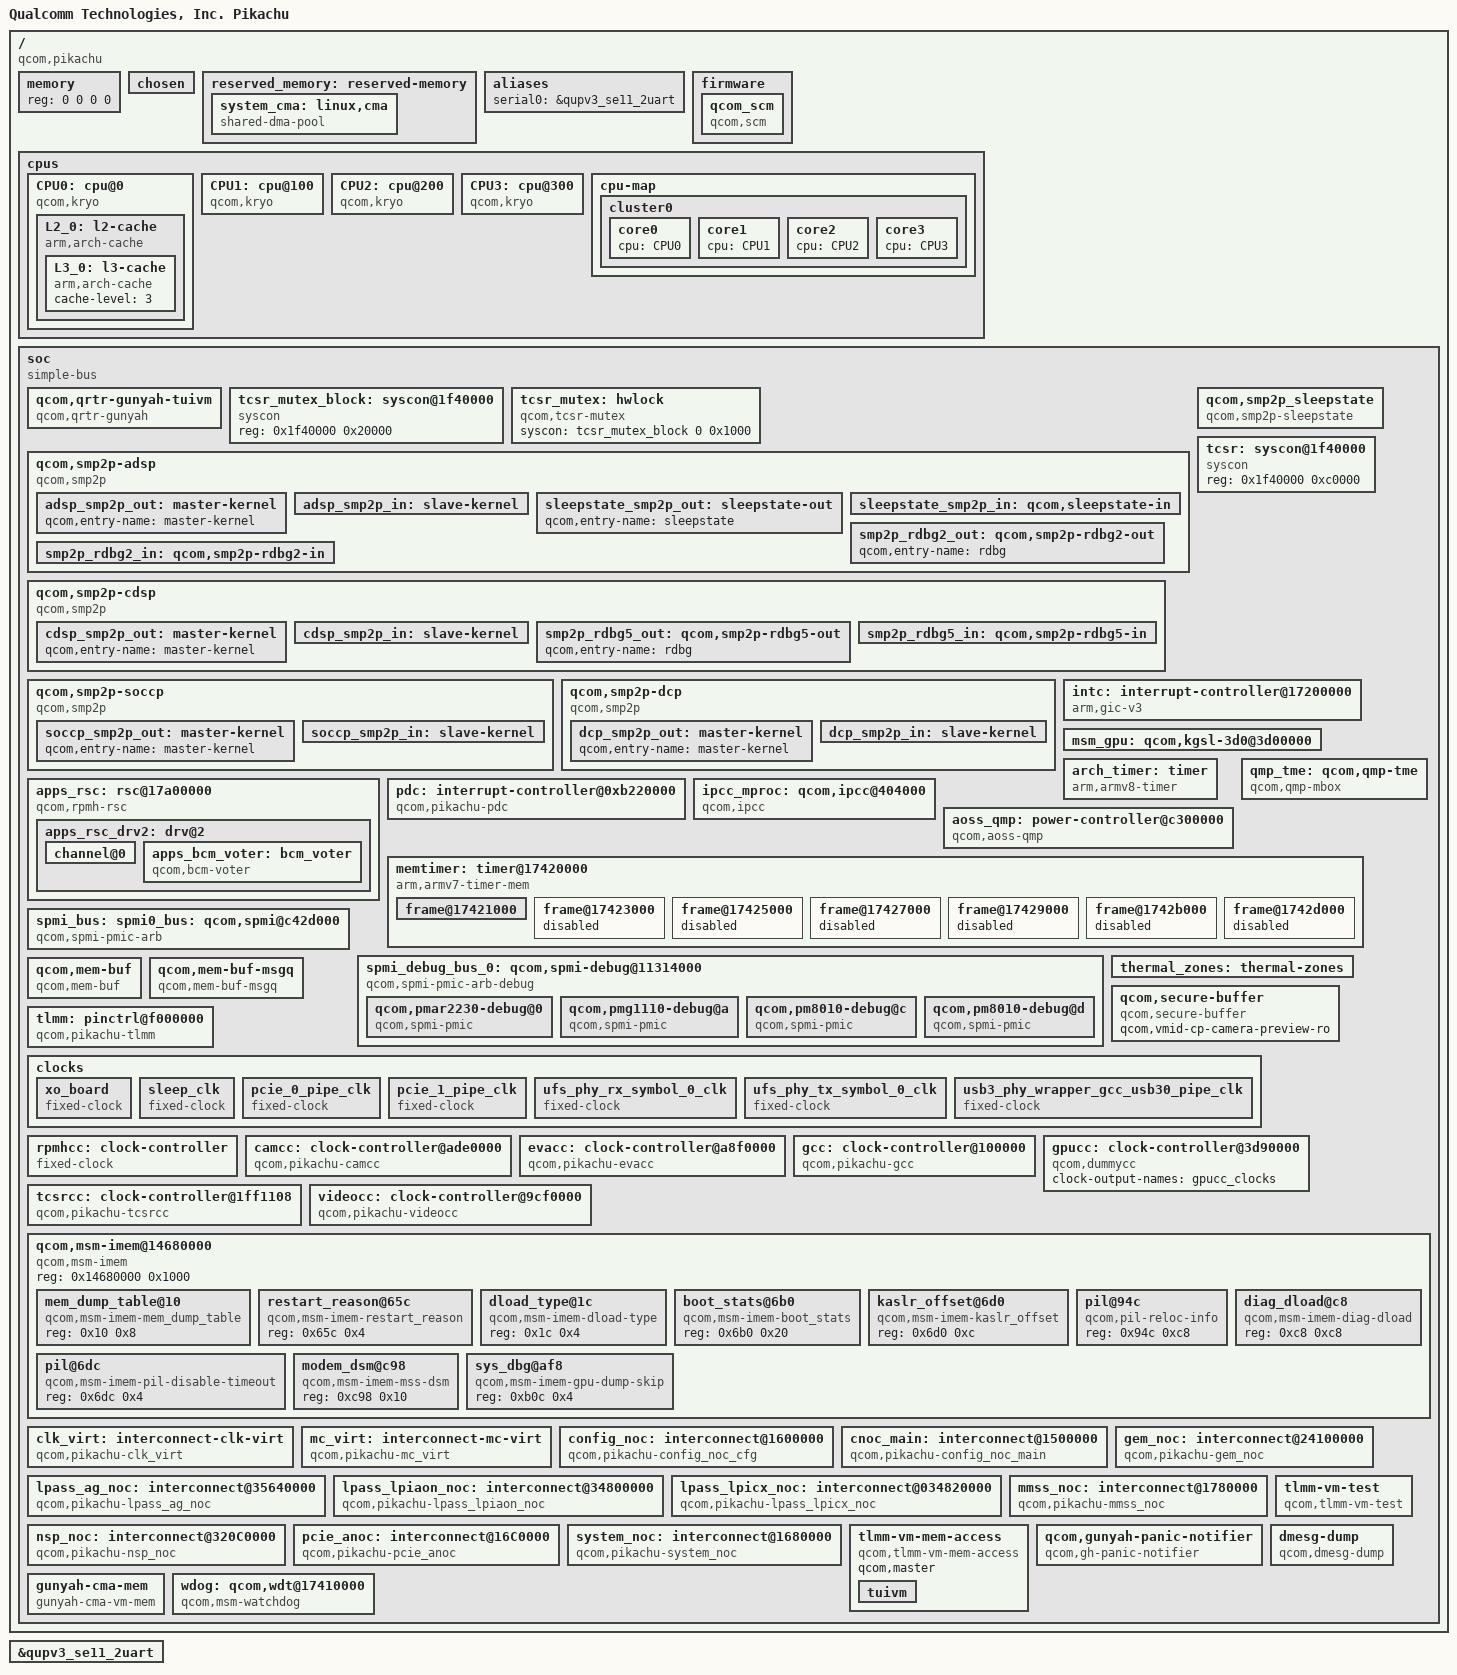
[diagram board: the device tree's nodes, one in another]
// SPDX-License-Identifier: BSD-3-Clause
/*
 * Copyright (c) Qualcomm Technologies, Inc. and/or its subsidiaries.
 */

#include <dt-bindings/interrupt-controller/arm-gic.h>
#include <dt-bindings/clock/qcom,rpmh.h>
#include <dt-bindings/clock/qcom,pikachu-camcc.h>
#include <dt-bindings/clock/qcom,pikachu-evacc.h>
#include <dt-bindings/clock/qcom,pikachu-gcc.h>
#include <dt-bindings/clock/qcom,pikachu-gpucc.h>
#include <dt-bindings/clock/qcom,pikachu-tcsrcc.h>
#include <dt-bindings/clock/qcom,pikachu-videocc.h>
#include <dt-bindings/interconnect/qcom,icc.h>
#include <dt-bindings/interconnect/qcom,pikachu.h>
#include <dt-bindings/regulator/qcom,rpmh-regulator-levels.h>
#include <dt-bindings/soc/qcom,rpmh-rsc.h>
#include <dt-bindings/soc/qcom,ipcc.h>
#include <dt-bindings/spmi/spmi.h>
#include <dt-bindings/mailbox/qcom-ipcc.h>
#include <dt-bindings/interrupt-controller/irq.h>

/ {
	model = "Qualcomm Technologies, Inc. Pikachu";
	compatible = "qcom,pikachu";
	qcom,msm-id = <736 0x10000>;
	interrupt-parent = <&intc>;

	#address-cells = <2>;
	#size-cells = <2>;
	memory { device_type = "memory"; reg = <0 0 0 0>; };

	chosen: chosen {
		bootargs = "kpti=0 log_buf_len=256K swiotlb=0 loop.max_part=7 loglevel=8 swiotlb=0 kasan=off cgroup_disable=pressure cgroup.memory=nokmem,nosocket disable_dma32=on restrict_cma_redirect=false";
	};

	reserved_memory: reserved-memory {};

	aliases {
		serial0 = &qupv3_se11_2uart;
	 };

	firmware: firmware {
		qcom_scm: qcom_scm { };
	};

	cpus {
		#address-cells = <2>;
		#size-cells = <0>;

		CPU0: cpu@0 {
			device_type = "cpu";
			compatible = "qcom,kryo";
			reg = <0x0 0x0>;
			enable-method = "spin-table";
			cpu-release-addr = <0x0 0x90000000>;
			next-level-cache = <&L2_0>;
			capacity-dmips-mhz = <1024>;
			dynamic-power-coefficient = <100>;
			#cooling-cells = <2>;
			L2_0: l2-cache {
				compatible = "arm,arch-cache";
				cache-level = <2>;
				next-level-cache = <&L3_0>;

				L3_0: l3-cache {
					compatible = "arm,arch-cache";
					cache-level = <3>;
				};
			};
		};

		CPU1: cpu@100 {
			device_type = "cpu";
			compatible = "qcom,kryo";
			reg = <0x0 0x100>;
			enable-method = "spin-table";
			cpu-release-addr = <0x0 0x90000000>;
			next-level-cache = <&L2_0>;
			capacity-dmips-mhz = <1024>;
			dynamic-power-coefficient = <100>;
			#cooling-cells = <2>;
		};

		CPU2: cpu@200 {
			device_type = "cpu";
			compatible = "qcom,kryo";
			reg = <0x0 0x200>;
			enable-method = "spin-table";
			cpu-release-addr = <0x0 0x90000000>;
			next-level-cache = <&L2_0>;
			capacity-dmips-mhz = <1024>;
			dynamic-power-coefficient = <100>;
			#cooling-cells = <2>;
		};

		CPU3: cpu@300 {
			device_type = "cpu";
			compatible = "qcom,kryo";
			reg = <0x0 0x300>;
			enable-method = "spin-table";
			cpu-release-addr = <0x0 0x90000000>;
			next-level-cache = <&L2_0>;
			capacity-dmips-mhz = <1024>;
			dynamic-power-coefficient = <100>;
			#cooling-cells = <2>;
		};

		cpu-map {
			cluster0 {
				core0 {
					cpu = <&CPU0>;
				};

				core1 {
					cpu = <&CPU1>;
				};

				core2 {
					cpu = <&CPU2>;
				};

				core3 {
					cpu = <&CPU3>;
				};
			};
		};
	};

	soc: soc { };

};

&soc {
	#address-cells = <1>;
	#size-cells = <1>;

	ranges = <0 0 0 0xffffffff>;
	compatible = "simple-bus";

	qcom,qrtr-gunyah-tuivm {
		compatible = "qcom,qrtr-gunyah";
		qcom,master;
		gunyah-label = <0x103>;
		peer-name = <2>;
	};

	tcsr_mutex_block: syscon@1f40000 {
		compatible = "syscon";
		reg = <0x1f40000 0x20000>;
	};

	tcsr_mutex: hwlock {
		compatible = "qcom,tcsr-mutex";
		syscon = <&tcsr_mutex_block 0 0x1000>;
		#hwlock-cells = <1>;
	};

	qcom,smp2p-adsp {
		compatible = "qcom,smp2p";
		qcom,smem = <443>, <429>;
		interrupt-parent = <&ipcc_mproc>;
		interrupts = <IPCC_CLIENT_LPASS IPCC_MPROC_SIGNAL_SMP2P
			      IRQ_TYPE_EDGE_RISING>;
		mboxes = <&ipcc_mproc IPCC_CLIENT_LPASS
			  IPCC_MPROC_SIGNAL_SMP2P>;
		qcom,local-pid = <0>;
		qcom,remote-pid = <2>;

		adsp_smp2p_out: master-kernel {
			qcom,entry-name = "master-kernel";
			#qcom,smem-state-cells = <1>;
		};

		adsp_smp2p_in: slave-kernel {
			qcom,entry-name = "slave-kernel";
			interrupt-controller;
			#interrupt-cells = <2>;
		};

		sleepstate_smp2p_out: sleepstate-out {
			qcom,entry-name = "sleepstate";
			#qcom,smem-state-cells = <1>;
		};

		sleepstate_smp2p_in: qcom,sleepstate-in {
			qcom,entry-name = "sleepstate_see";
			interrupt-controller;
			#interrupt-cells = <2>;
		};

		smp2p_rdbg2_out: qcom,smp2p-rdbg2-out {
			qcom,entry-name = "rdbg";
			#qcom,smem-state-cells = <1>;
		};

		smp2p_rdbg2_in: qcom,smp2p-rdbg2-in {
			qcom,entry-name = "rdbg";
			interrupt-controller;
			#interrupt-cells = <2>;
		};
	};

	qcom,smp2p-cdsp {
		compatible = "qcom,smp2p";
		qcom,smem = <94>, <432>;
		interrupt-parent = <&ipcc_mproc>;
		interrupts = <IPCC_CLIENT_CDSP IPCC_MPROC_SIGNAL_SMP2P
			      IRQ_TYPE_EDGE_RISING>;
		mboxes = <&ipcc_mproc IPCC_CLIENT_CDSP IPCC_MPROC_SIGNAL_SMP2P>;
		qcom,local-pid = <0>;
		qcom,remote-pid = <5>;

		cdsp_smp2p_out: master-kernel {
			qcom,entry-name = "master-kernel";
			#qcom,smem-state-cells = <1>;
		};

		cdsp_smp2p_in: slave-kernel {
			qcom,entry-name = "slave-kernel";
			interrupt-controller;
			#interrupt-cells = <2>;
		};

		smp2p_rdbg5_out: qcom,smp2p-rdbg5-out {
			qcom,entry-name = "rdbg";
			#qcom,smem-state-cells = <1>;
		};

		smp2p_rdbg5_in: qcom,smp2p-rdbg5-in {
			qcom,entry-name = "rdbg";
			interrupt-controller;
			#interrupt-cells = <2>;
		};
	};

	qcom,smp2p-soccp {
		compatible = "qcom,smp2p";
		qcom,smem = <617>, <616>;
		interrupt-parent = <&ipcc_mproc>;
		interrupts = <IPCC_CLIENT_SOCCP IPCC_MPROC_SIGNAL_SMP2P
			      IRQ_TYPE_EDGE_RISING>;
		mboxes = <&ipcc_mproc IPCC_CLIENT_SOCCP IPCC_MPROC_SIGNAL_SMP2P>;
		qcom,local-pid = <0>;
		qcom,remote-pid = <19>;

		soccp_smp2p_out: master-kernel {
			qcom,entry-name = "master-kernel";
			#qcom,smem-state-cells = <1>;
		};

		soccp_smp2p_in: slave-kernel {
			qcom,entry-name = "slave-kernel";
			interrupt-controller;
			#interrupt-cells = <2>;
		};
	};

	qcom,smp2p_sleepstate {
		compatible = "qcom,smp2p-sleepstate";
		qcom,smem-states = <&sleepstate_smp2p_out 0>;
		interrupt-parent = <&sleepstate_smp2p_in>;
		interrupts = <0 0>;
		interrupt-names = "smp2p-sleepstate-in";
	};


	qcom,smp2p-dcp {
		compatible = "qcom,smp2p";
		qcom,smem = <617>, <616>;
		interrupt-parent = <&ipcc_mproc>;
		interrupts = <IPCC_CLIENT_DCP IPCC_MPROC_SIGNAL_SMP2P
			      IRQ_TYPE_EDGE_RISING>;
		mboxes = <&ipcc_mproc IPCC_CLIENT_DCP IPCC_MPROC_SIGNAL_SMP2P>;
		qcom,local-pid = <0>;
		qcom,remote-pid = <22>;

		dcp_smp2p_out: master-kernel {
			qcom,entry-name = "master-kernel";
			#qcom,smem-state-cells = <1>;
		};

		dcp_smp2p_in: slave-kernel {
			qcom,entry-name = "slave-kernel";
			interrupt-controller;
			#interrupt-cells = <2>;
		};

	};

	tcsr: syscon@1f40000 {
		compatible = "syscon";
		reg = <0x1f40000 0xc0000>;
	};

	intc: interrupt-controller@17200000 {
		compatible = "arm,gic-v3";
		#interrupt-cells = <3>;
		interrupt-controller;
		#redistributor-regions = <1>;
		redistributor-stride = <0x0 0x20000>;
		reg = <0x17200000 0x10000>,       /* GICD */
		     <0x17260000 0xA0000>;       /* GICR * 8 */
		interrupts = <GIC_PPI 9 IRQ_TYPE_LEVEL_HIGH>;
	};

	msm_gpu: qcom,kgsl-3d0@3d00000 { };

	arch_timer: timer {
		compatible = "arm,armv8-timer";
		interrupts = <GIC_PPI 13 (GIC_CPU_MASK_SIMPLE(8) | IRQ_TYPE_LEVEL_LOW)>,
			     <GIC_PPI 14 (GIC_CPU_MASK_SIMPLE(8) | IRQ_TYPE_LEVEL_LOW)>,
			     <GIC_PPI 11 (GIC_CPU_MASK_SIMPLE(8) | IRQ_TYPE_LEVEL_LOW)>,
			     <GIC_PPI 12 (GIC_CPU_MASK_SIMPLE(8) | IRQ_TYPE_LEVEL_LOW)>;
		clock-frequency = <19200000>;
	};

	apps_rsc: rsc@17a00000 {
		label = "apps_rsc";
		compatible = "qcom,rpmh-rsc";
		reg = <0x17a00000 0x10000>,
		      <0x17a10000 0x10000>,
		      <0x17a20000 0x10000>;
		reg-names = "drv-0", "drv-1", "drv-2";
		qcom,drv-count = <3>;
		interrupts = <GIC_SPI 3 IRQ_TYPE_LEVEL_HIGH>,
			     <GIC_SPI 4 IRQ_TYPE_LEVEL_HIGH>,
			     <GIC_SPI 5 IRQ_TYPE_LEVEL_HIGH>;

		apps_rsc_drv2: drv@2 {
			qcom,drv-id = <2>;
			qcom,tcs-offset = <0xd00>;
			qcom,tcs-distance = <0x2a0>;

			channel@0 {
				 qcom,tcs-config = <ACTIVE_TCS    3>,
						   <SLEEP_TCS     2>,
						   <WAKE_TCS      2>,
						   <CONTROL_TCS   0>,
						   <FAST_PATH_TCS 1>;
			};

			apps_bcm_voter: bcm_voter {
				compatible = "qcom,bcm-voter";
			};
		};
	};

	pdc: interrupt-controller@0xb220000 {
		compatible = "qcom,pikachu-pdc", "qcom,pdc";
		reg = <0xb220000 0x10000>, <0x174000f0 0x64>;
		qcom,pdc-ranges = <0 221 1>, <1 227 2>, <3 238 4>,
				  <7 139 1>, <8 263 2>, <10 293 3>,
				  <13 156 1>, <14 297 2>, <16 348 2>,
				  <18 351 3>, <22 355 2>, <24 641 1>,
				  <25 358 1>, <26 376 2>, <28 443 1>,
				  <30 242 1>, <31 296 1>, <32 354 1>,
				  <33 357 1>, <34 444 3>, <37 472 1>,
				  <40 447 1>, <41 461 1>, <42 473 1>,
				  <43 462 1>, <44 584 1>, <45 586 1>,
				  <47 607 2>, <49 642 1>, <50 656 1>,
				  <51 527 1>, <52 476 3>, <57 235 1>,
				  <58 237 1>, <59 287 1>, <60 367 1>,
				  <61 505 1>, <62 605 1>, <63 372 2>,
				  <65 378 1>, <66 431 1>, <70 528 46>,
				  <116 609 31>, <147 63 1>, <148 716 12>,
				  <160 251 5>, <165 379 1>;
		#interrupt-cells = <2>;
		interrupt-parent = <&intc>;
		interrupt-controller;
	};

	ipcc_mproc: qcom,ipcc@404000 {
		compatible = "qcom,ipcc";
		reg = <0x404000 0x1000>;
		interrupts = <GIC_SPI 229 IRQ_TYPE_LEVEL_HIGH>;
		interrupt-controller;
		#interrupt-cells = <3>;
		#mbox-cells = <2>;
	};

	aoss_qmp: power-controller@c300000 {
		compatible = "qcom,aoss-qmp";
		reg = <0xc300000 0x400>;
		interrupt-parent = <&ipcc_mproc>;
		interrupts = <IPCC_CLIENT_AOP
			      IPCC_MPROC_SIGNAL_GLINK_QMP
			      IRQ_TYPE_EDGE_RISING>;
		mboxes = <&ipcc_mproc IPCC_CLIENT_AOP
			  IPCC_MPROC_SIGNAL_GLINK_QMP>;

		#power-domain-cells = <1>;
		#clock-cells = <0>;
	};

	qmp_tme: qcom,qmp-tme {
		compatible = "qcom,qmp-mbox";
		qcom,remote-pid = <14>;
		mboxes = <&ipcc_mproc IPCC_CLIENT_TME
			  IPCC_MPROC_SIGNAL_GLINK_QMP>;
		mbox-names = "tme_qmp";
		interrupt-parent = <&ipcc_mproc>;
		interrupts = <IPCC_CLIENT_TME
			      IPCC_MPROC_SIGNAL_GLINK_QMP
			      IRQ_TYPE_EDGE_RISING>;

		label = "tme";
		qcom,early-boot;
		priority = <0>;
		mbox-desc-offset = <0x0>;
		#mbox-cells = <1>;
	};

	memtimer: timer@17420000 {
		#address-cells = <1>;
		#size-cells = <1>;
		ranges;
		compatible = "arm,armv7-timer-mem";
		reg = <0x17420000 0x1000>;
		clock-frequency = <19200000>;

		frame@17421000 {
			frame-number = <0>;
			interrupts = <GIC_SPI 8 IRQ_TYPE_LEVEL_HIGH>,
				     <GIC_SPI 6 IRQ_TYPE_LEVEL_HIGH>;
			reg = <0x17421000 0x1000>,
			      <0x17422000 0x1000>;
		};

		frame@17423000 {
			frame-number = <1>;
			interrupts = <GIC_SPI 9 IRQ_TYPE_LEVEL_HIGH>;
			reg = <0x17423000 0x1000>;
			status = "disabled";
		};

		frame@17425000 {
			frame-number = <2>;
			interrupts = <GIC_SPI 10 IRQ_TYPE_LEVEL_HIGH>;
			reg = <0x17425000 0x1000>;
			status = "disabled";
		};

		frame@17427000 {
			frame-number = <3>;
			interrupts = <GIC_SPI 11 IRQ_TYPE_LEVEL_HIGH>;
			reg = <0x17427000 0x1000>;
			status = "disabled";
		};

		frame@17429000 {
			frame-number = <4>;
			interrupts = <GIC_SPI 12 IRQ_TYPE_LEVEL_HIGH>;
			reg = <0x17429000 0x1000>;
			status = "disabled";
		};

		frame@1742b000 {
			frame-number = <5>;
			interrupts = <GIC_SPI 13 IRQ_TYPE_LEVEL_HIGH>;
			reg = <0x1742b000 0x1000>;
			status = "disabled";
		};

		frame@1742d000 {
			frame-number = <6>;
			interrupts = <GIC_SPI 14 IRQ_TYPE_LEVEL_HIGH>;
			reg = <0x1742d000 0x1000>;
			status = "disabled";
		};
	};

	spmi_bus: spmi0_bus: qcom,spmi@c42d000 {
		compatible = "qcom,spmi-pmic-arb";
		reg = <0x0 0xc42d000 0x0 0x4000>,
		      <0x0 0xc400000 0x0 0x3000>,
		      <0x0 0xc500000 0x0 0x400000>,
		      <0x0 0xc440000 0x0 0x80000>,
		      <0x0 0xc4c0000 0x0 0x10000>;
		reg-names = "cnfg", "core", "chnls", "obsrvr", "intr";
		interrupts-extended = <&pdc 1 IRQ_TYPE_LEVEL_HIGH>;
		interrupt-names = "periph_irq";
		interrupt-controller;
		#interrupt-cells = <4>;
		#address-cells = <2>;
		#size-cells = <0>;
		cell-index = <0>;
		qcom,channel = <0>;
		qcom,ee = <0>;
		qcom,bus-id = <0>;
	};

	spmi_debug_bus_0: qcom,spmi-debug@11314000  {
		compatible = "qcom,spmi-pmic-arb-debug";
		reg = <0x0 0x11314000 0x0 0x60>,
		      <0x0 0x221c8784 0x0 0x4>;
		reg-names = "core", "fuse";
		clocks = <&aoss_qmp>;
		clock-names = "core_clk";
		qcom,fuse-enable-bit = <14>;
		#address-cells = <1>;
		#size-cells = <0>;
		depends-on-supply = <&spmi0_bus>;

		qcom,pmar2230-debug@0 {
			compatible = "qcom,spmi-pmic";
			reg = <0 SPMI_USID>;
			#address-cells = <2>;
			#size-cells = <0>;
			qcom,can-sleep;
		};

		qcom,pmg1110-debug@a {
			compatible = "qcom,spmi-pmic";
			reg = <10 SPMI_USID>;
			#address-cells = <2>;
			#size-cells = <0>;
			qcom,can-sleep;
		};

		qcom,pm8010-debug@c {
			compatible = "qcom,spmi-pmic";
			reg = <12 SPMI_USID>;
			#address-cells = <2>;
			#size-cells = <0>;
			qcom,can-sleep;
		};

		qcom,pm8010-debug@d {
			compatible = "qcom,spmi-pmic";
			reg = <13 SPMI_USID>;
			#address-cells = <2>;
			#size-cells = <0>;
			qcom,can-sleep;
		};
	};

	thermal_zones: thermal-zones {};

	qcom,mem-buf {
		compatible = "qcom,mem-buf";
		qcom,mem-buf-capabilities = "supplier";
		qcom,vmid = <3>;
	};

	qcom,mem-buf-msgq {
		compatible = "qcom,mem-buf-msgq";
	};

	qcom,secure-buffer {
		compatible = "qcom,secure-buffer";
		qcom,vmid-cp-camera-preview-ro;
	};

	tlmm: pinctrl@f000000 {
		compatible = "qcom,pikachu-tlmm";
		reg = <0xF000000 0x1000000>;
		interrupts = <GIC_SPI 208 IRQ_TYPE_LEVEL_HIGH>;
		gpio-controller;
		#gpio-cells = <2>;
		interrupt-controller;
		#interrupt-cells = <2>;
		wakeup-parent = <&pdc>;
	};

	clocks {
		xo_board: xo_board {
			compatible = "fixed-clock";
			clock-frequency = <19200000>;
			clock-output-names = "xo_board";
			#clock-cells = <0>;
		};

		sleep_clk: sleep_clk {
			compatible = "fixed-clock";
			clock-frequency = <32000>;
			clock-output-names = "sleep_clk";
			#clock-cells = <0>;
		};

		pcie_0_pipe_clk: pcie_0_pipe_clk {
			compatible = "fixed-clock";
			clock-frequency = <1000>;
			clock-output-names = "pcie_0_pipe_clk";
			#clock-cells = <0>;
		};

		pcie_1_pipe_clk: pcie_1_pipe_clk {
			compatible = "fixed-clock";
			clock-frequency = <1000>;
			clock-output-names = "pcie_1_pipe_clk";
			#clock-cells = <0>;
		};

		ufs_phy_rx_symbol_0_clk: ufs_phy_rx_symbol_0_clk {
			compatible = "fixed-clock";
			clock-frequency = <1000>;
			clock-output-names = "ufs_phy_rx_symbol_0_clk";
			#clock-cells = <0>;
		};

		ufs_phy_tx_symbol_0_clk: ufs_phy_tx_symbol_0_clk {
			compatible = "fixed-clock";
			clock-frequency = <1000>;
			clock-output-names = "ufs_phy_tx_symbol_0_clk";
			#clock-cells = <0>;
		};

		usb3_phy_wrapper_gcc_usb30_pipe_clk: usb3_phy_wrapper_gcc_usb30_pipe_clk {
			compatible = "fixed-clock";
			clock-frequency = <1000>;
			clock-output-names = "usb3_phy_wrapper_gcc_usb30_pipe_clk";
			#clock-cells = <0>;
		};
	};

	rpmhcc: clock-controller {
		compatible = "fixed-clock";
		clock-output-names = "rpmh_clocks";
		clock-frequency = <19200000>;
		#clock-cells = <1>;
	};

	camcc: clock-controller@ade0000 {
		compatible = "qcom,pikachu-camcc", "syscon";
		reg = <0xade0000 0x20000>;
		reg-name = "cc_base";
		vdd_mm-supply = <&VDD_MM_LEVEL>;
		vdd_mx-supply = <&VDD_MX_LEVEL>;
		vdd_mxc-supply = <&VDD_MXC_LEVEL>;
		vdd_mm_mxc_voter-supply = <&VDD_MM_MXC_VOTER_LEVEL>;
		clocks = <&rpmhcc RPMH_CXO_CLK>,
			 <&sleep_clk>, <&gcc GCC_CAMERA_AHB_CLK>;
		clock-names = "bi_tcxo",
			      "sleep_clk", "iface";
		interconnects = <&mmss_noc MASTER_CAMNOC_HF &mc_virt SLAVE_EBI1>;
		interconnect-names = "cam-to-ddr";
		#clock-cells = <1>;
		#reset-cells = <1>;
		#power-domain-cells = <1>;
	};

	evacc: clock-controller@a8f0000 {
		compatible = "qcom,pikachu-evacc", "syscon";
		reg = <0xa8f0000 0x10000>;
		reg-name = "cc_base";
		vdd_mm-supply = <&VDD_MM_LEVEL>;
		vdd_mxc-supply = <&VDD_MXC_LEVEL>;
		clocks = <&rpmhcc RPMH_CXO_CLK>,
			 <&sleep_clk>,
			 <&gcc GCC_EVA_AHB_CLK>;
		clock-names = "bi_tcxo",
			      "sleep_clk",
			      "iface";
		#clock-cells = <1>;
		#reset-cells = <1>;
		#power-domain-cells = <1>;
	};

	gcc: clock-controller@100000 {
		compatible = "qcom,pikachu-gcc", "syscon";
		reg = <0x100000 0x1f4200>;
		reg-name = "cc_base";
		vdd_cx-supply = <&VDD_CX_LEVEL>;
		vdd_mx-supply = <&VDD_MX_LEVEL>;
		clocks = <&rpmhcc RPMH_CXO_CLK>,
			 <&pcie_0_pipe_clk>,
			 <&pcie_1_pipe_clk>,
			 <&sleep_clk>,
			 <&ufs_phy_rx_symbol_0_clk>,
			 <&ufs_phy_tx_symbol_0_clk>,
			 <&usb3_phy_wrapper_gcc_usb30_pipe_clk>;
		clock-names = "bi_tcxo",
			      "pcie_0_pipe_clk",
			      "pcie_1_pipe_clk",
			      "sleep_clk",
			      "ufs_phy_rx_symbol_0_clk",
			      "ufs_phy_tx_symbol_0_clk",
			      "usb3_phy_wrapper_gcc_usb30_pipe_clk";
		#clock-cells = <1>;
		#reset-cells = <1>;
		#power-domain-cells = <1>;
	};

	gpucc: clock-controller@3d90000 {
		compatible = "qcom,dummycc";
		clock-output-names = "gpucc_clocks";
		#clock-cells = <1>;
		#reset-cells = <1>;
		#power-domain-cells = <1>;
	};

	tcsrcc: clock-controller@1ff1108 {
		compatible = "qcom,pikachu-tcsrcc", "syscon";
		reg = <0x1ff1108 0x18>;
		reg-name = "cc_base";
		#clock-cells = <1>;
		#reset-cells = <1>;
	};

	videocc: clock-controller@9cf0000 {
		compatible = "qcom,pikachu-videocc", "syscon";
		reg = <0x9cf0000 0x10000>;
		reg-name = "cc_base";
		vdd_mm-supply = <&VDD_MM_LEVEL>;
		vdd_mxc-supply = <&VDD_MXC_LEVEL>;
		clocks = <&rpmhcc RPMH_CXO_CLK>,
			<&sleep_clk>,
			<&gcc GCC_VIDEO_AHB_CLK>;
		clock-names = "bi_tcxo",
				"sleep_clk",
				"iface";
		#clock-cells = <1>;
		#reset-cells = <1>;
		#power-domain-cells = <1>;
	};

	qcom,msm-imem@14680000 {
		compatible = "qcom,msm-imem";
		reg = <0x14680000 0x1000>;
		ranges = <0x0 0x14680000 0x1000>;
		#address-cells = <1>;
		#size-cells = <1>;

		mem_dump_table@10 {
			compatible = "qcom,msm-imem-mem_dump_table";
			reg = <0x10 0x8>;
		};

		restart_reason@65c {
			compatible = "qcom,msm-imem-restart_reason";
			reg = <0x65c 0x4>;
		};

		dload_type@1c {
			compatible = "qcom,msm-imem-dload-type";
			reg = <0x1c 0x4>;
		};

		boot_stats@6b0 {
			compatible = "qcom,msm-imem-boot_stats";
			reg = <0x6b0 0x20>;
		};

		kaslr_offset@6d0 {
			compatible = "qcom,msm-imem-kaslr_offset";
			reg = <0x6d0 0xc>;
		};

		pil@94c {
			compatible = "qcom,pil-reloc-info";
			reg = <0x94c 0xc8>;
		};

		pil@6dc {
			compatible = "qcom,msm-imem-pil-disable-timeout";
			reg = <0x6dc 0x4>;
		};

		diag_dload@c8 {
			compatible = "qcom,msm-imem-diag-dload";
			reg = <0xc8 0xc8>;
		};

		modem_dsm@c98 {
			compatible = "qcom,msm-imem-mss-dsm";
			reg = <0xc98 0x10>;
		};

		sys_dbg@af8 {
			compatible = "qcom,msm-imem-gpu-dump-skip";
			reg = <0xb0c 0x4>;
		};
	};

	clk_virt: interconnect-clk-virt {
		compatible = "qcom,pikachu-clk_virt";
		#interconnect-cells = <1>;
		qcom,bcm-voter-names = "hlos";
		qcom,bcm-voters = <&apps_bcm_voter>;
		qcom,skip-qos;
	};

	mc_virt: interconnect-mc-virt {
		compatible = "qcom,pikachu-mc_virt";
		#interconnect-cells = <1>;
		qcom,bcm-voter-names = "hlos";
		qcom,bcm-voters = <&apps_bcm_voter>;
		qcom,skip-qos;
	};

	config_noc: interconnect@1600000 {
		compatible = "qcom,pikachu-config_noc_cfg";
		reg = <0x01600000 0x7200>;
		#interconnect-cells = <1>;
		qcom,bcm-voter-names = "hlos";
		qcom,bcm-voters = <&apps_bcm_voter>;
		qcom,skip-qos;
	};

	cnoc_main: interconnect@1500000 {
		compatible = "qcom,pikachu-config_noc_main";
		reg = <0x01500000 0x1a200>;
		#interconnect-cells = <1>;
		qcom,bcm-voter-names = "hlos";
		qcom,bcm-voters = <&apps_bcm_voter>;
		qcom,skip-qos;
	};

	gem_noc: interconnect@24100000 {
		compatible = "qcom,pikachu-gem_noc";
		reg = <0x24100000 0x161080>;
		#interconnect-cells = <1>;
		qcom,bcm-voter-names = "hlos";
		qcom,bcm-voters = <&apps_bcm_voter>;
		qcom,skip-qos;
	};

	lpass_ag_noc: interconnect@35640000 {
		compatible = "qcom,pikachu-lpass_ag_noc";
		reg = <0x35640000 0xe080>;
		#interconnect-cells = <1>;
		qcom,bcm-voter-names = "hlos";
		qcom,bcm-voters = <&apps_bcm_voter>;
		qcom,skip-qos;
	};

	lpass_lpiaon_noc: interconnect@34800000 {
		compatible = "qcom,pikachu-lpass_lpiaon_noc";
		reg = <0x34800000 0x19080>;
		#interconnect-cells = <1>;
		qcom,bcm-voter-names = "hlos";
		qcom,bcm-voters = <&apps_bcm_voter>;
		qcom,skip-qos;
	};

	lpass_lpicx_noc: interconnect@034820000 {
		compatible = "qcom,pikachu-lpass_lpicx_noc";
		reg = <0x34820000 0x44080>;
		#interconnect-cells = <1>;
		qcom,bcm-voter-names = "hlos";
		qcom,bcm-voters = <&apps_bcm_voter>;
		qcom,skip-qos;
	};

	mmss_noc: interconnect@1780000 {
		compatible = "qcom,pikachu-mmss_noc";
		reg = <0x01780000 0x6c000>;
		#interconnect-cells = <1>;
		qcom,bcm-voter-names = "hlos";
		qcom,bcm-voters = <&apps_bcm_voter>;
		qcom,skip-qos;
	};

	nsp_noc: interconnect@320C0000 {
		compatible = "qcom,pikachu-nsp_noc";
		reg = <0x320c0000 0x1f400>;
		#interconnect-cells = <1>;
		qcom,bcm-voter-names = "hlos";
		qcom,bcm-voters = <&apps_bcm_voter>;
		qcom,skip-qos;
	};

	pcie_anoc: interconnect@16C0000 {
		compatible = "qcom,pikachu-pcie_anoc";
		reg = <0x016c0000 0xe800>;
		#interconnect-cells = <1>;
		qcom,bcm-voter-names = "hlos";
		qcom,bcm-voters = <&apps_bcm_voter>;
		qcom,skip-qos;
	};

	system_noc: interconnect@1680000 {
		compatible = "qcom,pikachu-system_noc";
		reg = <0x01680000 0x2e400>;
		#interconnect-cells = <1>;
		qcom,bcm-voter-names = "hlos";
		qcom,bcm-voters = <&apps_bcm_voter>;
		qcom,skip-qos;
	};

	thermal_zones: thermal-zones {
	};

	tlmm-vm-mem-access {
		compatible = "qcom,tlmm-vm-mem-access";
		qcom,master;

		tuivm {
			qcom,label = <0x08>;
			qcom,vmid = <45>;
			tlmm-vm-gpio-list = <&tlmm 12 0>;
		};
	};

	tlmm-vm-test {
		compatible = "qcom,tlmm-vm-test";
		qcom,master;
		tlmm-vm-gpio-list = <&tlmm 12 0>;
	};

	qcom,gunyah-panic-notifier {
		compatible = "qcom,gh-panic-notifier";
		qcom,primary-vm;
		gunyah-label = <0x109>;
		peer-name = <2>;
		memory-region = <&vm_comm_mem>;
		shared-buffer-size = <0x1000>;
	};

	dmesg-dump {
		compatible = "qcom,dmesg-dump";
		qcom,primary-vm;
		gunyah-label = <0x107>;
		peer-name = <2>;
		memory-region = <&vm_comm_mem>;
		shared-buffer-size = <0x1000>;
	};

	gunyah-cma-mem {
		compatible = "gunyah-cma-vm-mem";
		memory-region = <&trust_ui_vm_mem>;
		memory-region-names = "trustedvm_cma";
	};

	wdog: qcom,wdt@17410000 {
		compatible = "qcom,msm-watchdog";
		reg = <0x17410000 0x1000>;
		reg-names = "wdt-base";
		interrupts = <GIC_SPI 0 IRQ_TYPE_LEVEL_HIGH>,
			     <GIC_SPI 1 IRQ_TYPE_LEVEL_HIGH>;
		status = "ok";
	};

};

&firmware {
	qcom_scm {
		compatible = "qcom,scm";
	};
};

#include "pikachu-reserved-memory.dtsi"

&reserved_memory {
	#address-cells = <2>;
	#size-cells = <2>;
	ranges;

	/* global autoconfigured region for contiguous allocations */
	system_cma: linux,cma {
		compatible = "shared-dma-pool";
		alloc-ranges = <0x0 0x00000000 0x0 0xffffffff>;
		reusable;
		alignment = <0x0 0x400000>;
		size = <0x0 0x2400000>;
		linux,cma-default;
	};

};

#include "msm-arm-smmu-pikachu.dtsi"
#include "pikachu-pinctrl.dtsi"
#include "pikachu-regulators.dtsi"
#include "pikachu-dma-heaps.dtsi"
#include "pikachu-qupv3.dtsi"
#include "msm-rdbg.dtsi"

&qupv3_se11_2uart {
	status = "ok";
};

#include "pikachu-thermal.dtsi"
